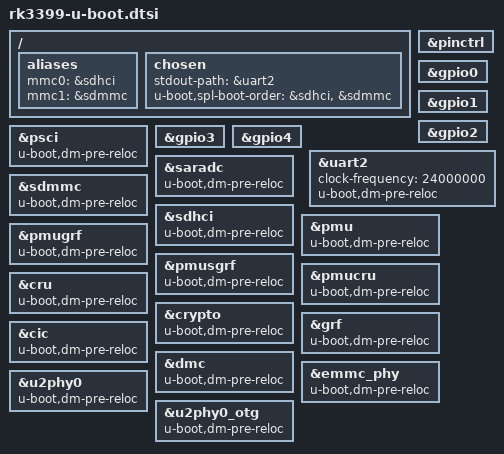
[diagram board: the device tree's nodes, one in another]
/*
 * (C) Copyright 2018 Rockchip Electronics Co., Ltd
 *
 * SPDX-License-Identifier:     GPL-2.0+
 */

/ {
	aliases {
		mmc0 = &sdhci;
		mmc1 = &sdmmc;
	};

	chosen {
		stdout-path = &uart2;
		u-boot,spl-boot-order = &sdhci, &sdmmc;
	};
};

&psci {
	u-boot,dm-pre-reloc;
	status = "okay";
};


&pinctrl {
	u-boot,dm-spl;
	status = "okay";
};

&gpio0 {
	u-boot,dm-spl;
};

&gpio1 {
	u-boot,dm-spl;
};

&gpio2 {
	u-boot,dm-spl;
};

&gpio3 {
	u-boot,dm-spl;
};

&gpio4 {
	u-boot,dm-spl;
};

&uart2 {
	clock-frequency = <24000000>;
	u-boot,dm-pre-reloc;
};

&saradc {
	u-boot,dm-pre-reloc;
};

&sdmmc {
	u-boot,dm-pre-reloc;
};

&sdhci {
	u-boot,dm-pre-reloc;
};

&pmu {
	u-boot,dm-pre-reloc;
};

&pmugrf {
	u-boot,dm-pre-reloc;
};

&pmusgrf {
	u-boot,dm-pre-reloc;
};

&pmucru {
	u-boot,dm-pre-reloc;
};

&cru {
	u-boot,dm-pre-reloc;
};

&crypto {
	u-boot,dm-pre-reloc;
};

&grf {
	u-boot,dm-pre-reloc;
};

&cic {
	u-boot,dm-pre-reloc;
};

&dmc {
	u-boot,dm-pre-reloc;
};

&emmc_phy {
	u-boot,dm-pre-reloc;
};

&u2phy0 {
	u-boot,dm-pre-reloc;
	status = "okay";
};

&u2phy0_otg {
	u-boot,dm-pre-reloc;
	status = "okay";
};
